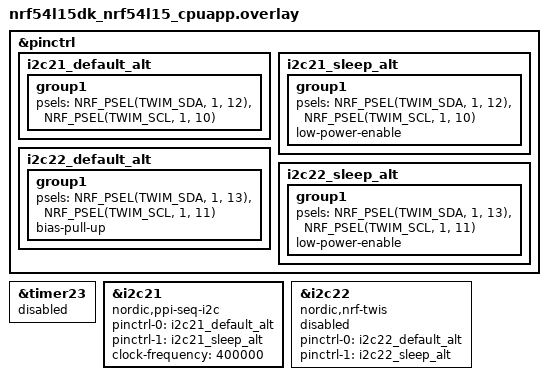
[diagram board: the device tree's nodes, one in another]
/*
 * Copyright (c) 2026 Nordic Semiconductor ASA
 *
 * SPDX-License-Identifier: LicenseRef-Nordic-5-Clause
 */

/* Test requires loopbacks:
 * - between P1.11 and P1.10.
 * - between P1.12 and P1.13,
 */

&pinctrl {
	i2c21_default_alt: i2c21_default_alt {
		group1 {
			psels = <NRF_PSEL(TWIM_SDA, 1, 12)>,
				<NRF_PSEL(TWIM_SCL, 1, 10)>;
		};
	};

	i2c21_sleep_alt: i2c21_sleep_alt {
		group1 {
			psels = <NRF_PSEL(TWIM_SDA, 1, 12)>,
				<NRF_PSEL(TWIM_SCL, 1, 10)>;
			low-power-enable;
		};
	};

	i2c22_default_alt: i2c22_default_alt {
		group1 {
			psels = <NRF_PSEL(TWIM_SDA, 1, 13)>,
				<NRF_PSEL(TWIM_SCL, 1, 11)>;
			bias-pull-up;
		};
	};

	i2c22_sleep_alt: i2c22_sleep_alt {
		group1 {
			psels = <NRF_PSEL(TWIM_SDA, 1, 13)>,
				<NRF_PSEL(TWIM_SCL, 1, 11)>;
			low-power-enable;
		};
	};
};

test_timer: &timer23 {
	status = "reserved";
};

dut: &i2c21 {
	compatible = "nordic,ppi-seq-i2c";
	status = "okay";
	pinctrl-0 = <&i2c21_default_alt>;
	pinctrl-1 = <&i2c21_sleep_alt>;
	pinctrl-names = "default", "sleep";
	clock-frequency = <400000>;
};

tester: &i2c22 {
	compatible = "nordic,nrf-twis";
	status = "reserved";
	pinctrl-0 = <&i2c22_default_alt>;
	pinctrl-1 = <&i2c22_sleep_alt>;
	pinctrl-names = "default", "sleep";
};
